# ESP32-S3-ULP register map
Vendor: ESPRESSIF SYSTEMS (SHANGHAI) CO., LTD.; Series: RISC-V ULP; File version: 2
32-bit RISC-V MCU
CPU: RV32IMC r0p0, little endian, no MPU, no FPU, 0 interrupt priority bits
Address unit: 32 bits
Registers are 32-bit, read-write, reset 0x0 unless marked. A register's access mark holds for its fields unless they carry their own. Offsets are from the block's base; lines under a group give offsets from that group; [hi:lo] are bit positions; {n}, {i} and the like mark numbered series; 'fields as' and 'values as' point back to an identical list; <NAME> marks a mode.

## Memory map
0x00008000 RTC_CNTL size 0x15C — Real-Time Clock Control
0x0000A400 RTC_IO size 0xF0 — Low-power Input/Output
0x0000C800 SENS size 0x11C — SENS Peripheral
0x0000EC00 RTC_I2C size 0x7C — Low-power I2C (Inter-Integrated Circuit) Controller

## Interrupts
0 TOUCH_DONE_INT (SENS)
1 TOUCH_INACTIVE_INT (SENS)
2 TOUCH_ACTIVE_INT (SENS)
3 SARADC1_DONE_INT (SENS)
4 SARADC2_DONE_INT (SENS)
5 TSENS_DONE_INT (SENS)
6 RISCV_START_INT (RTC_CNTL)
7 SW_INT (RTC_CNTL)
8 SWD_INT (RTC_CNTL)
9 TOUCH_TIME_OUT_INT (SENS)
10 TOUCH_APPROACH_LOOP_DONE_INT (SENS)
11 TOUCH_SCAN_DONE_INT (SENS)

## RTC_CNTL — Real-Time Clock Control
Base 0x00008000
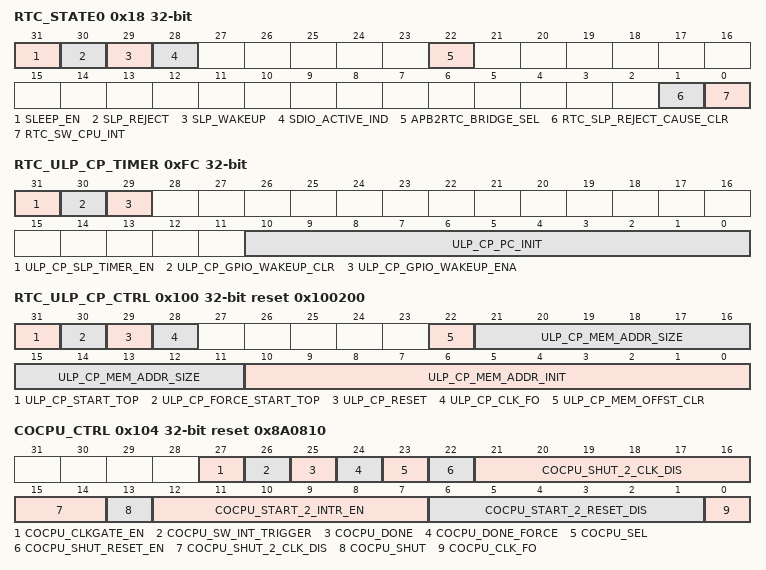
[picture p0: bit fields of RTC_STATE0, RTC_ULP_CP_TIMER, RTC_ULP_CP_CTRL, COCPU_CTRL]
0x18 RTC_STATE0 access per field — configure chip sleep
  [31] SLEEP_EN rw — sleep enable bit
  [30] SLP_REJECT rw — leep reject bit
  [29] SLP_WAKEUP rw — leep wakeup bit
  [28] SDIO_ACTIVE_IND ro — SDIO active indication
  [22] APB2RTC_BRIDGE_SEL rw — 1: APB to RTC using bridge, 0: APB to RTC using sync
  [1] RTC_SLP_REJECT_CAUSE_CLR wo — clear rtc sleep reject cause
  [0] RTC_SW_CPU_INT wo — rtc software interrupt to main cpu
0xFC RTC_ULP_CP_TIMER access per field — configure ulp
  [31] ULP_CP_SLP_TIMER_EN rw — ULP-coprocessor timer enable bit
  [30] ULP_CP_GPIO_WAKEUP_CLR wo — ULP-coprocessor wakeup by GPIO state clear
  [29] ULP_CP_GPIO_WAKEUP_ENA rw — ULP-coprocessor wakeup by GPIO enable
  [10:0] ULP_CP_PC_INIT rw — ULP-coprocessor PC initial address
0x100 RTC_ULP_CP_CTRL access per field reset 0x100200 — configure ulp
  [31] ULP_CP_START_TOP rw — Write 1 to start ULP-coprocessor
  [30] ULP_CP_FORCE_START_TOP rw — 1: ULP-coprocessor is started by SW
  [29] ULP_CP_RESET rw — ulp coprocessor clk software reset
  [28] ULP_CP_CLK_FO rw — ulp coprocessor clk force on
  [22] ULP_CP_MEM_OFFST_CLR wo — No public
  [21:11] ULP_CP_MEM_ADDR_SIZE rw — No public
  [10:0] ULP_CP_MEM_ADDR_INIT rw — No public
0x104 COCPU_CTRL access per field reset 0x8A0810 — configure ulp-riscv
  [27] COCPU_CLKGATE_EN rw — open ulp-riscv clk gate
  [26] COCPU_SW_INT_TRIGGER wo — trigger cocpu register interrupt
  [25] COCPU_DONE rw — done signal used by riscv to control timer.
  [24] COCPU_DONE_FORCE rw — 1: select riscv done 0: select ulp done
  [23] COCPU_SEL rw — 1: old ULP 0: new riscV
  [22] COCPU_SHUT_RESET_EN rw — to reset cocpu
  [21:14] COCPU_SHUT_2_CLK_DIS rw — time from shut cocpu to disable clk
  [13] COCPU_SHUT rw — to shut cocpu
  [12:7] COCPU_START_2_INTR_EN rw — time from start cocpu to give start interrupt
  [6:1] COCPU_START_2_RESET_DIS rw — time from start cocpu to pull down reset
  [0] COCPU_CLK_FO rw — cocpu clk force on
0x134 RTC_ULP_CP_TIMER_1 reset 0xC800 — configure ulp sleep time
  [31:8] ULP_CP_TIMER_SLP_CYCLE — sleep cycles for ULP-coprocessor timer

## Licence text in the file
Copyright 2025 Espressif Systems (Shanghai) PTE LTD Licensed under the Apache License, Version 2.0 (the "License"); you may not use this file except in compliance with the License. You may obtain a copy of the License at http://www.apache.org/licenses/LICENSE-2.0 Unless required by applicable law or agreed to in writing, software distributed under the License is distributed on an "AS IS" BASIS, WITHOUT WARRANTIES OR CONDITIONS OF ANY KIND, either express or implied. See the License for the specific language governing permissions and limitations under the License.
